# RX64M_TMR0_Pilot register map
File version: 1.0
RX64M_TMR0_Pilot peripheral registers generated from iodefine.h (pilot).
Registers are 8-bit, read-write, reset 0x0 unless marked. A register's access mark holds for its fields unless they carry their own. Offsets are from the block's base; lines under a group give offsets from that group; [hi:lo] are bit positions; {n}, {i} and the like mark numbered series; 'fields as' and 'values as' point back to an identical list; <NAME> marks a mode.

## Memory map
0x00088200 TMR0 size 0xD
0x00088210 TMR2 size 0xD

## TMR0
Base 0x00088200
Same registers: TMR2 0x00088210
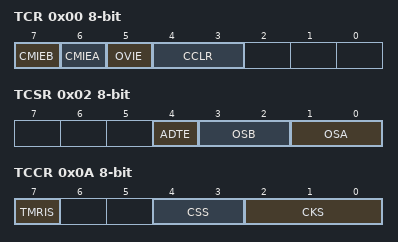
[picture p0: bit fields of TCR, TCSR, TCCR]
0x00 TCR
  [7] CMIEB, [6] CMIEA, [5] OVIE, [4:3] CCLR
0x02 TCSR
  [4] ADTE, [3:2] OSB, [1:0] OSA
0x04 TCORA reset 0xFF
0x06 TCORB reset 0xFF
0x08 TCNT
0x0A TCCR
  [7] TMRIS, [4:3] CSS, [2:0] CKS
0x0C TCSTR
  [0] TCS
